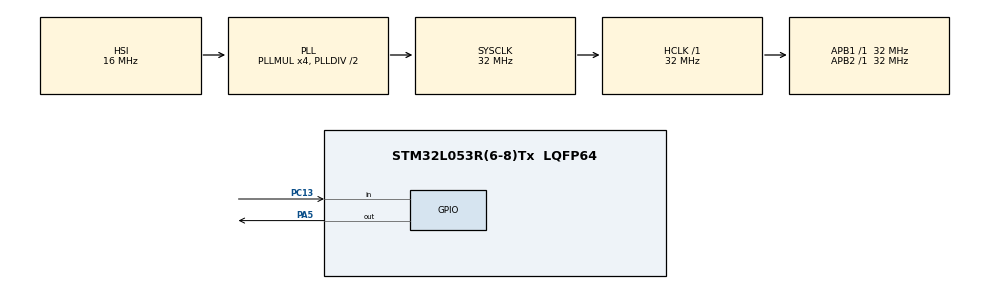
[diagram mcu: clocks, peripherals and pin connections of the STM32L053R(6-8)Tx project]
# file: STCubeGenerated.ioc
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Mcu.Family=STM32L0
Mcu.Name=STM32L053R(6-8)Tx
Mcu.Package=LQFP64
PA5.Signal=GPIO_Output
PC13.Signal=GPIO_Input
ProjectManager.HeapSize=0x200
ProjectManager.StackSize=0x400
ProjectManager.TargetToolchain=MDK-ARM V5
RCC.AHBFreq_Value=32000000
RCC.APB1Freq_Value=32000000
RCC.APB1TimFreq_Value=32000000
RCC.APB2Freq_Value=32000000
RCC.APB2TimFreq_Value=32000000
RCC.HCLKFreq_Value=32000000
RCC.HSE_VALUE=8000000
RCC.HSI16_VALUE=16000000
RCC.HSI48_VALUE=48000000
RCC.HSI_VALUE=16000000
RCC.LSE_VALUE=32768
RCC.MSI_VALUE=2097000
RCC.PLLMUL=RCC_PLLMUL_4
RCC.SYSCLKFreq_VALUE=32000000
RCC.SYSCLKSource=RCC_SYSCLKSOURCE_PLLCLK
RCC.VCOOutputFreq_Value=64000000
VP_RNG_VS_RNG.Mode=RNG_Activate
board=STCubeGenerated

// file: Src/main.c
/**
  ******************************************************************************
  * File Name          : main.c
  * Description        : Main program body
  ******************************************************************************
  ** This notice applies to any and all portions of this file
  * that are not between comment pairs USER CODE BEGIN and
  * USER CODE END. Other portions of this file, whether
  * inserted by the user or by software development tools
  * are owned by their respective copyright owners.
  *
  * COPYRIGHT(c) 2021 STMicroelectronics
  *
  * Redistribution and use in source and binary forms, with or without modification,
  * are permitted provided that the following conditions are met:
  *   1. Redistributions of source code must retain the above copyright notice,
  *      this list of conditions and the following disclaimer.
  *   2. Redistributions in binary form must reproduce the above copyright notice,
  *      this list of conditions and the following disclaimer in the documentation
  *      and/or other materials provided with the distribution.
  *   3. Neither the name of STMicroelectronics nor the names of its contributors
  *      may be used to endorse or promote products derived from this software
  *      without specific prior written permission.
  *
  * THIS SOFTWARE IS PROVIDED BY THE COPYRIGHT HOLDERS AND CONTRIBUTORS "AS IS"
  * AND ANY EXPRESS OR IMPLIED WARRANTIES, INCLUDING, BUT NOT LIMITED TO, THE
  * IMPLIED WARRANTIES OF MERCHANTABILITY AND FITNESS FOR A PARTICULAR PURPOSE ARE
  * DISCLAIMED. IN NO EVENT SHALL THE COPYRIGHT HOLDER OR CONTRIBUTORS BE LIABLE
  * FOR ANY DIRECT, INDIRECT, INCIDENTAL, SPECIAL, EXEMPLARY, OR CONSEQUENTIAL
  * DAMAGES (INCLUDING, BUT NOT LIMITED TO, PROCUREMENT OF SUBSTITUTE GOODS OR
  * SERVICES; LOSS OF USE, DATA, OR PROFITS; OR BUSINESS INTERRUPTION) HOWEVER
  * CAUSED AND ON ANY THEORY OF LIABILITY, WHETHER IN CONTRACT, STRICT LIABILITY,
  * OR TORT (INCLUDING NEGLIGENCE OR OTHERWISE) ARISING IN ANY WAY OUT OF THE USE
  * OF THIS SOFTWARE, EVEN IF ADVISED OF THE POSSIBILITY OF SUCH DAMAGE.
  *
  ******************************************************************************
  */

#include "main.h"
#include "stm32l0xx_hal.h"

/* USER CODE BEGIN Includes */
#include <math.h>
#include <stdio.h>
#include "arm_math.h"

/* USER CODE END Includes */

RNG_HandleTypeDef hrng;

/* USER CODE BEGIN PV */
/* Private variables ---------------------------------------------------------*/
/*
Those parameters can be generated with the python library scikit-learn.
*/
arm_gaussian_naive_bayes_instance_f32 S;

#define NB_OF_CLASSES 3
#define VECTOR_DIMENSION 2

const float32_t theta[NB_OF_CLASSES*VECTOR_DIMENSION] = {
  1.660420379236184f, 0.7267260354065609f,
  1.8632722141252336f, 1.4293493184624575f,
  0.23793190379498694f, 1.374447314157124f
}; /**< Mean values for the Gaussians */

const float32_t sigma[NB_OF_CLASSES*VECTOR_DIMENSION] = {
  3.5852746767398034f, 4.035913043820933f,
  4.167812351992022f, 3.1546219197887986f,
  4.333556328823355f, 3.4281538954869664f
}; /**< Variances for the Gaussians */

const float32_t classPriors[NB_OF_CLASSES] = {
  0.3333333333333333f, 0.3333333333333333f, 0.3333333333333333f
}; /**< Class prior probabilities */
/* USER CODE END PV */

void SystemClock_Config(void);
static void MX_GPIO_Init(void);
static void MX_RNG_Init(void);

/* USER CODE BEGIN PFP */
/* Private function prototypes -----------------------------------------------*/

/* USER CODE END PFP */

/* USER CODE BEGIN 0 */

/**
  * Override default HAL_GetTick function
  */
uint32_t HAL_GetTick (void) {
  static uint32_t ticks = 0U;
         uint32_t i;

  if (osKernelGetState () == osKernelRunning) {
    return ((uint32_t)osKernelGetTickCount ());
  }

  /* If Kernel is not running wait approximately 1 ms then increment
     and return auxiliary tick counter value */
  for (i = (SystemCoreClock >> 14U); i > 0U; i--) {
    __NOP(); __NOP(); __NOP(); __NOP(); __NOP(); __NOP();
    __NOP(); __NOP(); __NOP(); __NOP(); __NOP(); __NOP();
  }
  return ++ticks;
}
/* USER CODE END 0 */

int main(void)
{

  /* USER CODE BEGIN 1 */
	uint32_t randNum0, randNum1;   // Variables for storing Random numbers

  /* USER CODE END 1 */

  /* MCU Configuration----------------------------------------------------------*/

  /* Reset of all peripherals, Initializes the Flash interface and the Systick. */
  HAL_Init();

  /* Configure the system clock */
  SystemClock_Config();

  /* USER CODE BEGIN SysInit */
  SystemCoreClockUpdate();
  /* USER CODE END SysInit */

  /* Initialize all configured peripherals */
  MX_GPIO_Init();
  MX_RNG_Init();

  /* USER CODE BEGIN 2 */

  /* Initialize CMSIS-RTOS2 */
  osKernelInitialize ();

  /* Create application main thread */
  osThreadNew(app_main, NULL, &app_main_attr);

  /* Start thread execution */
  osKernelStart();

  /* USER CODE END 2 */

  /* Infinite loop */
  /* USER CODE BEGIN WHILE */
/* Array of input data */
  float32_t in[2];

  /* Result of the classifier */
  float32_t result[NB_OF_CLASSES];
  float32_t maxProba;
  uint32_t index;

  S.vectorDimension = VECTOR_DIMENSION;
  S.numberOfClasses = NB_OF_CLASSES;
  S.theta = theta;
  S.sigma = sigma;
  S.classPriors = classPriors;
  S.epsilon=4.551809276196062e-09f;

  while (1)
		{
			HAL_RNG_GenerateRandomNumber(&hrng, &randNum0);     // RHG for naive input
			in[0] = randNum0 * 0.00000001;											// Converting to float value

			HAL_RNG_GenerateRandomNumber(&hrng, &randNum1);			// RHG for naive input
			in[1] = randNum1 * 0.00000001;											// Converting to float value

			index = arm_gaussian_naive_bayes_predict_f32(&S, in, result);

			maxProba = result[index];

			#if defined(SEMIHOSTING)
				printf("Class = %d\n", index);
			#endif

			HAL_Delay(10);

		}; /* main function does not return */
}

/** System Clock Configuration
*/
void SystemClock_Config(void)
{

  RCC_OscInitTypeDef RCC_OscInitStruct;
  RCC_ClkInitTypeDef RCC_ClkInitStruct;
  RCC_PeriphCLKInitTypeDef PeriphClkInit;

    /**Configure the main internal regulator output voltage
    */
  __HAL_PWR_VOLTAGESCALING_CONFIG(PWR_REGULATOR_VOLTAGE_SCALE1);

    /**Initializes the CPU, AHB and APB busses clocks
    */
  RCC_OscInitStruct.OscillatorType = RCC_OSCILLATORTYPE_HSI;
  RCC_OscInitStruct.HSIState = RCC_HSI_ON;
  RCC_OscInitStruct.HSICalibrationValue = 16;
  RCC_OscInitStruct.PLL.PLLState = RCC_PLL_ON;
  RCC_OscInitStruct.PLL.PLLSource = RCC_PLLSOURCE_HSI;
  RCC_OscInitStruct.PLL.PLLMUL = RCC_PLLMUL_4;
  RCC_OscInitStruct.PLL.PLLDIV = RCC_PLLDIV_2;
  if (HAL_RCC_OscConfig(&RCC_OscInitStruct) != HAL_OK)
  {
    _Error_Handler(__FILE__, __LINE__);
  }

    /**Initializes the CPU, AHB and APB busses clocks
    */
  RCC_ClkInitStruct.ClockType = RCC_CLOCKTYPE_HCLK|RCC_CLOCKTYPE_SYSCLK
                              |RCC_CLOCKTYPE_PCLK1|RCC_CLOCKTYPE_PCLK2;
  RCC_ClkInitStruct.SYSCLKSource = RCC_SYSCLKSOURCE_PLLCLK;
  RCC_ClkInitStruct.AHBCLKDivider = RCC_SYSCLK_DIV1;
  RCC_ClkInitStruct.APB1CLKDivider = RCC_HCLK_DIV1;
  RCC_ClkInitStruct.APB2CLKDivider = RCC_HCLK_DIV1;

  if (HAL_RCC_ClockConfig(&RCC_ClkInitStruct, FLASH_LATENCY_1) != HAL_OK)
  {
    _Error_Handler(__FILE__, __LINE__);
  }

  PeriphClkInit.PeriphClockSelection = RCC_PERIPHCLK_USB;
  PeriphClkInit.UsbClockSelection = RCC_USBCLKSOURCE_PLL;
  if (HAL_RCCEx_PeriphCLKConfig(&PeriphClkInit) != HAL_OK)
  {
    _Error_Handler(__FILE__, __LINE__);
  }

    /**Configure the Systick interrupt time
    */
  HAL_SYSTICK_Config(HAL_RCC_GetHCLKFreq()/1000);

    /**Configure the Systick
    */
  HAL_SYSTICK_CLKSourceConfig(SYSTICK_CLKSOURCE_HCLK);

  /* SysTick_IRQn interrupt configuration */
  HAL_NVIC_SetPriority(SysTick_IRQn, 3, 0);
}

/* RNG init function */
static void MX_RNG_Init(void)
{

  hrng.Instance = RNG;
  if (HAL_RNG_Init(&hrng) != HAL_OK)
  {
    _Error_Handler(__FILE__, __LINE__);
  }

}

/** Configure pins
*/
static void MX_GPIO_Init(void)
{

  GPIO_InitTypeDef GPIO_InitStruct;

  /* GPIO Ports Clock Enable */
  __HAL_RCC_GPIOC_CLK_ENABLE();
  __HAL_RCC_GPIOA_CLK_ENABLE();

  /*Configure GPIO pin Output Level */
  HAL_GPIO_WritePin(GPIOA, GPIO_PIN_5, GPIO_PIN_RESET);

  /*Configure GPIO pin : PC13 */
  GPIO_InitStruct.Pin = GPIO_PIN_13;
  GPIO_InitStruct.Mode = GPIO_MODE_INPUT;
  GPIO_InitStruct.Pull = GPIO_NOPULL;
  HAL_GPIO_Init(GPIOC, &GPIO_InitStruct);

  /*Configure GPIO pin : PA5 */
  GPIO_InitStruct.Pin = GPIO_PIN_5;
  GPIO_InitStruct.Mode = GPIO_MODE_OUTPUT_PP;
  GPIO_InitStruct.Pull = GPIO_NOPULL;
  GPIO_InitStruct.Speed = GPIO_SPEED_FREQ_LOW;
  HAL_GPIO_Init(GPIOA, &GPIO_InitStruct);

}

void _Error_Handler(char * file, int line)
{
  while(1)
  {
  }
}

/************************ (C) COPYRIGHT STMicroelectronics *****END OF FILE****/
